# M471M_R1_S register map
File version: 1.0
Registers are 32-bit, read-write, reset 0x0 unless marked. A register's access mark holds for its fields unless they carry their own. Offsets are from the block's base; [hi:lo] are bit positions; {n}, {i} and the like mark numbered series; 'fields as' and 'values as' point back to an identical list.

## CLK — CLK Register Map
Base 0x40000200
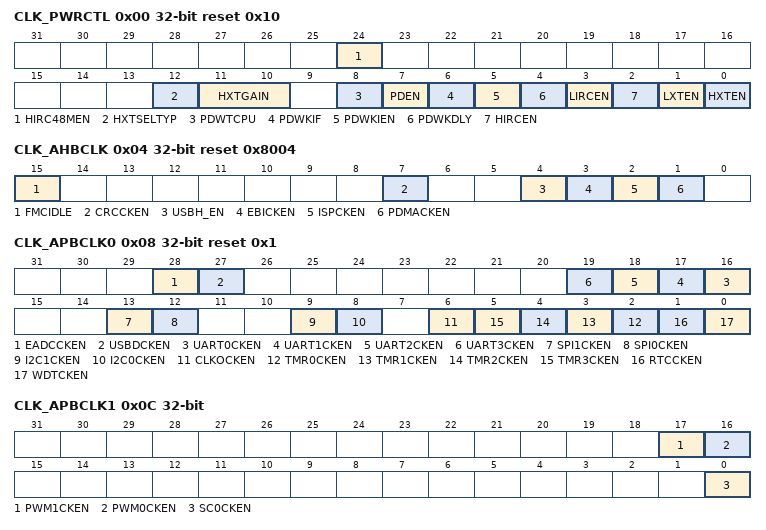
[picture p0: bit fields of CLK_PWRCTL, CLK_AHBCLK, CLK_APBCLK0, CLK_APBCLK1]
0x00 CLK_PWRCTL reset 0x10 (reset mask 0xFFFFFFF0) — System Power-down Control Register
  [24] HIRC48MEN — HIRC48M Enable Bit (Write Protect). Note: This bit is write protected. Refer to the SYS_REGLCTL register.
    0=48 MHz internal high speed RC oscillator (HIRC48M) Disabled; 1=48 MHz internal high speed RC oscillator (HIRC48M) Enabled
  [12] HXTSELTYP — HXT Crystal Type Select Bit (Write Protect). This is a protected register. Please refer to open lock sequence to program it. Note: This bit is write protected. Refer to the SYS_REGLCTL register.
    0=Select INV type; 1=Select GM type
  [11:10] HXTGAIN — HXT Gain Control Bit (Write Protect). This is a protected register. Please refer to open lock sequence to program it. Gain control is used to enlarge the gain of crystal to make sure crystal work normally. If gain control is enabled, crystal will consume more power than gain control off. Note: This bit is write protected. Refer to the SYS_REGLCTL register.
    0=HXT frequency is lower than from 8 MHz; 1=HXT frequency is from 8 MHz to 12 MHz; 2=HXT frequency is from 12 MHz to 16 MHz; 3=HXT frequency is higher than 16 MHz
  [8] PDWTCPU — this Bit Control the Power-down Entry Condition (Write Protect). Note: This bit is write protected. Refer to the SYS_REGLCTL register.
    0=Chip enters Power-down mode when the PDEN bit is set to 1; 1=Chip enters Power-down mode when the both PDWTCPU and PDEN bits are set to 1 and CPU runs WFI instruction
  [7] PDEN — System Power-down Enable (Write Protect). When this bit is set to 1, Power-down mode is enabled and chip Power-down behavior will depend on the PDWTCPU bit. (a) If the PDWTCPU is 0, then the chip enters Power-down mode immediately after the PDEN bit set. (default) (b) if the PDWTCPU is 1, then the chip keeps active till the CPU sleep mode is also active and then the chip enters Power-down mode. When chip wakes up from Power-down mode, this bit is auto cleared. Users need to set this bit again for next Power-down. In Power-down mode, HXT and the HIRC will be disabled in this mode, but LXT and LIRC are not controlled by Power-down mode. In Power-down mode, the PLL and system clock are disabled, and ignored the clock source selection. The clocks of peripheral are not controlled by Power-down mode, if the peripheral clock source is from LXT or LIRC. Note: This bit is write protected. Refer to the SYS_REGLCTL register.
    0=Chip operating normally or chip in idle mode because of WFI command; 1=Chip enters Power-down mode instant or wait CPU sleep command WFI
  [6] PDWKIF — Power-down Mode Wake-up Interrupt Status. Set by 'Power-down wake-up event', it indicates that resume from Power-down mode' The flag is set if the EINT0~5, GPIO, USBD, UART0~3, WDT, BOD, RTC, TMR0~3, I2C0~1 wake-up occurred. Note1: Write 1 to clear the bit to 0. Note2: This bit works only if PDWKIEN (CLK_PWRCTL[5]) set to 1.
  [5] PDWKIEN — Power-down Mode Wake-up Interrupt Enable Bit (Write Protect). Note1: The interrupt will occur when both PDWKIF and PDWKIEN are high. Note2: This bit is write protected. Refer to the SYS_REGLCTL register.
    0=Power-down mode wake-up interrupt Disabled; 1=Power-down mode wake-up interrupt Enabled
  [4] PDWKDLY — Enable the Wake-up Delay Counter (Write Protect). When the chip wakes up from Power-down mode, the clock control will delay certain clock cycles to wait system clock stable. The delayed clock cycle is 4096 clock cycles when chip works at 4~20 MHz external high speed crystal oscillator (HXT), and 256 clock cycles when chip works at 22.1184 MHz internal high speed RC oscillator (HIRC). Note: This bit is write protected. Refer to the SYS_REGLCTL register.
    0=Clock cycles delay Disabled; 1=Clock cycles delay Enabled
  [3] LIRCEN — LIRC Enable Bit (Write Protect). Note: This bit is write protected. Refer to the SYS_REGLCTL register.
    0=10 kHz internal low speed RC oscillator (LIRC) Disabled; 1=10 kHz internal low speed RC oscillator (LIRC) Enabled
  [2] HIRCEN — HIRC Enable Bit (Write Protect). Note: This bit is write protected. Refer to the SYS_REGLCTL register.
    0=22.1184 MHz internal high speed RC oscillator (HIRC) Disabled; 1=22.1184 MHz internal high speed RC oscillator (HIRC) Enabled
  [1] LXTEN — LXT Enable Bit (Write Protect). Note: This bit is write protected. Refer to the SYS_REGLCTL register.
    0=32.768 kHz external low speed crystal (LXT) Disabled; 1=32.768 kHz external low speed crystal (LXT) Enabled
  [0] HXTEN — HXT Enable Bit (Write Protect). The bit default value is set by flash controller user configuration register CONFIG0 [26:24]. When the default clock source is from HXT, this bit is set to 1 automatically. Note: This bit is write protected. Refer to the SYS_REGLCTL register.
    0=4~20 MHz xxternal high speed crystal (HXT) Disabled; 1=4~20 MHz external high speed crystal (HXT) Enabled
0x04 CLK_AHBCLK reset 0x8004 — AHB Devices Clock Enable Control Register
  [15] FMCIDLE — Flash Memory Controller Clock Enable Bit in IDLE Mode
    0=FMC peripheral clock Disabled when chip operating in IDLE mode; 1=FMC peripheral clock Enabled when chip operating in IDLE mode
  [7] CRCCKEN — CRC Generator Controller Clock Enable Bit
    0=CRC peripheral clock Disabled; 1=CRC peripheral clock Enabled
  [4] USBH_EN — USB HOST Controller Clock Enable Control
    0=USB HOST engine clock Disabled; 1=USB HOST engine clock Enabled
  [3] EBICKEN — EBI Controller Clock Enable Bit
    0=EBI peripheral clock Disabled; 1=EBI peripheral clock Enabled
  [2] ISPCKEN — Flash ISP Controller Clock Enable Bit
    0=Flash ISP peripheral clock Disabled; 1=Flash ISP peripheral clock Enabled
  [1] PDMACKEN — PDMA Controller Clock Enable Bit
    0=PDMA peripheral clock Disabled; 1=PDMA peripheral clock Enabled
0x08 CLK_APBCLK0 reset 0x1 — APB Devices Clock Enable Control Register 0
  [28] EADCCKEN — Enhanced Analog-digital-converter (EADC) Clock Enable Bit
    0=EADC clock Disabled; 1=EADC clock Enabled
  [27] USBDCKEN — USB Device Clock Enable Bit
    0=USB Device clock Disabled; 1=USB Device clock Enabled
  [n+16] UART{n}CKEN (n=0..3) — UART{n} Clock Enable Bit
    0=UART{n} clock Disabled; 1=UART{n} clock Enabled
  [13] SPI1CKEN — SPI1 Clock Enable Bit
    0=SPI1 clock Disabled; 1=SPI1 clock Enabled
  [12] SPI0CKEN — SPI0 Clock Enable Bit
    0=SPI0 clock Disabled; 1=SPI0 clock Enabled
  [9] I2C1CKEN — I2C1 Clock Enable Bit
    0=I2C1 clock Disabled; 1=I2C1 clock Enabled
  [8] I2C0CKEN — I2C0 Clock Enable Bit
    0=I2C0 clock Disabled; 1=I2C0 clock Enabled
  [6] CLKOCKEN — CLKO Clock Enable Bit
    0=CLKO clock Disabled; 1=CLKO clock Enabled
  [n+2] TMR{n}CKEN (n=0..3) — Timer{n} Clock Enable Bit
    0=Timer{n} clock Disabled; 1=Timer{n} clock Enabled
  [1] RTCCKEN — Real-time-clock APB Interface Clock Enable Bit. This bit is used to control the RTC APB clock only. The RTC peripheral clock source is selected from RTCSEL(CLK_CLKSEL3[8]). It can be selected to 32.768 kHz external low speed crystal or 10 kHz internal low speed RC oscillator (LIRC).
    0=RTC APB clock Disabled; 1=RTC APB clock Enabled
  [0] WDTCKEN — Watchdog Timer Clock Enable Bit (Write Protect). Note: This bit is write protected. Refer to the SYS_REGLCTL register.
    0=Watchdog timer clock Disabled; 1=Watchdog timer clock Enabled
0x0C CLK_APBCLK1 — APB Devices Clock Enable Control Register 1
  [17] PWM1CKEN — PWM1 Clock Enable Bit
    0=PWM1 clock Disabled; 1=PWM1 clock Enabled
  [16] PWM0CKEN — PWM0 Clock Enable Bit
    0=PWM0 clock Disabled; 1=PWM0 clock Enabled
  [0] SC0CKEN — SC0 Clock Enable Bit
    0=SC0 clock Disabled; 1=SC0 clock Enabled
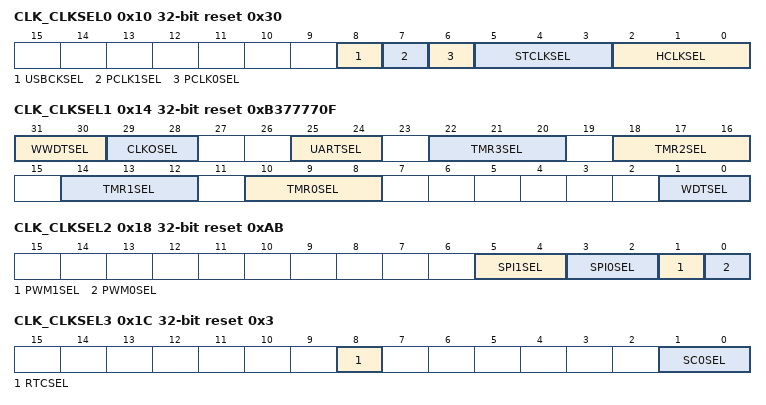
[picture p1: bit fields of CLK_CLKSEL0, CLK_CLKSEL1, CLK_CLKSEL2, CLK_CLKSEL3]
0x10 CLK_CLKSEL0 reset 0x30 (reset mask 0xFFFFFFF0) — Clock Source Select Control Register 0
  [8] USBCKSEL — USB Clock Source Selection (Write Protect). Note: This bit is write protected. Refer to the SYS_REGLCTL register.
    0=USBH and USBD clock source from PLL; 1=USBH and USBD clock source from HIRC48M
  [7] PCLK1SEL — PCLK1 Clock Source Selection (Write Protect). Note: This bit is write protected. Refer to the SYS_REGLCTL register.
    0=APB1 bUS clock source from HCLK; 1=APB1 bUS clock source from HCLK/2
  [6] PCLK0SEL — PCLK0 Clock Source Selection (Write Protect). Note: This bit is write protected. Refer to the SYS_REGLCTL register.
    0=APB0 bUS clock source from HCLK; 1=APB0 bUS clock source from HCLK/2
  [5:3] STCLKSEL — Cortex-M4 SysTick Clock Source Selection (Write Protect). Note: This bit is write protected. Refer to the SYS_REGLCTL register.
    0=Clock source from HXT; 1=Clock source from LXT; 2=Clock source from HXT/2; 3=Clock source from HCLK/2; 7=Clock source from HIRC/2
  [2:0] HCLKSEL — HCLK Clock Source Selection (Write Protect). Before clock switching, the related clock sources (both pre-select and new-select) must be turned on. The default value is reloaded from the value of CFOSC (CONFIG0[26:24]) in user configuration register of Flash controller by any reset. Therefore the default value is either 000b or 111b. Note: This bit is write protected. Refer to the SYS_REGLCTL register.
    0=Clock source from HXT; 1=Clock source from LXT; 2=Clock source from PLL; 3=Clock source from LIRC; 7=Clock source from HIRC
0x14 CLK_CLKSEL1 reset 0xB377770F — Clock Source Select Control Register 1
  [31:30] WWDTSEL — Window Watchdog Timer Clock Source Selection
    2=Clock source from HCLK/2048; 3=Clock source from 10 kHz internal low speed RC oscillator (LIRC)
  [29:28] CLKOSEL — Clock Divider Clock Source Selection
    0=Clock source from 4~20 MHz external high speed crystal oscillator (HXT); 1=Clock source from 32.768 kHz external low speed crystal oscillator (LXT); 2=Clock source from HCLK; 3=Clock source from 22.1184 MHz internal high speed RC oscillator (HIRC)
  [25:24] UARTSEL — UART Clock Source Selection
    0=Clock source from 4~20 MHz external high speed crystal oscillator (HXT); 1=Clock source from PLL; 2=Clock source from 32.768 kHz external low speed crystal oscillator (LXT); 3=Clock source from 22.1184 MHz internal high speed RC oscillator (HIRC)
  [22:20] TMR3SEL — TIMER3 Clock Source Selection
    0=Clock source from 4~20 MHz external high speed crystal oscillator (HXT); 1=Clock source from 32.768 kHz external low speed crystal oscillator (LXT); 2=Clock source from PCLK1; 3=Clock source from external clock T3 pin; 5=Clock source from 10 kHz internal low speed RC oscillator (LIRC); 7=Clock source from 22.1184 MHz internal high speed RC oscillator (HIRC)
  [18:16] TMR2SEL — TIMER2 Clock Source Selection
    0=Clock source from 4~20 MHz external high speed crystal oscillator (HXT); 1=Clock source from 32.768 kHz external low speed crystal oscillator (LXT); 2=Clock source from PCLK1; 3=Clock source from external clock T2 pin; 5=Clock source from 10 kHz internal low speed RC oscillator (LIRC); 7=Clock source from 22.1184 MHz internal high speed RC oscillator (HIRC)
  [14:12] TMR1SEL — TIMER1 Clock Source Selection
    0=Clock source from 4~20 MHz external high speed crystal oscillator (HXT); 1=Clock source from 32.768 kHz external low speed crystal oscillator (LXT); 2=Clock source from PCLK0; 3=Clock source from external clock T1 pin; 5=Clock source from 10 kHz internal low speed RC oscillator (LIRC); 7=Clock source from 22.1184 MHz internal high speed RC oscillator (HIRC)
  [10:8] TMR0SEL — TIMER0 Clock Source Selection
    0=Clock source from 4~20 MHz external high speed crystal oscillator (HXT); 1=Clock source from 32.768 kHz external low speed crystal oscillator (LXT); 2=Clock source from PCLK0; 3=Clock source from external clock T0 pin; 5=Clock source from 10 kHz internal low speed RC oscillator (LIRC); 7=Clock source from 22.1184 MHz internal high speed RC oscillator (HIRC)
  [1:0] WDTSEL — Watchdog Timer Clock Source Selection (Write Protect). Note: This bit is write protected. Refer to the SYS_REGLCTL register.
    1=Clock source from 32.768 kHz external low speed crystal oscillator (LXT); 2=Clock source from HCLK/2048; 3=Clock source from 10 kHz internal low speed RC oscillator (LIRC)
0x18 CLK_CLKSEL2 reset 0xAB — Clock Source Select Control Register 2
  [5:4] SPI1SEL — SPI1 Clock Source Selection
    0=Clock source from 4~20 MHz external high speed crystal oscillator (HXT); 1=Clock source from PLL; 2=Clock source from PCLK1; 3=Clock source from 22.1184 MHz internal high speed RC oscillator (HIRC)
  [3:2] SPI0SEL — SPI0 Clock Source Selection
    0=Clock source from 4~20 MHz external high speed crystal oscillator (HXT); 1=Clock source from PLL; 2=Clock source from PCLK0; 3=Clock source from 22.1184 MHz internal high speed RC oscillator (HIRC)
  [1] PWM1SEL — PWM1 Clock Source Selection. The peripheral clock source of PWM1 is defined by PWM1SEL.
    0=Clock source from PLL; 1=Clock source from PCLK1
  [0] PWM0SEL — PWM0 Clock Source Selection. The peripheral clock source of PWM0 is defined by PWM0SEL.
    0=Clock source from PLL; 1=Clock source from PCLK0
0x1C CLK_CLKSEL3 reset 0x3 — Clock Source Select Control Register 3
  [8] RTCSEL — RTC Clock Source Selection
    0=Clock source from 32.768 kHz external low speed crystal oscillator (LXT); 1=Clock source from 10 kHz internal low speed RC oscillator (LIRC)
  [1:0] SC0SEL — SC0 Clock Source Selection
    values as CLK_CLKSEL2.SPI0SEL
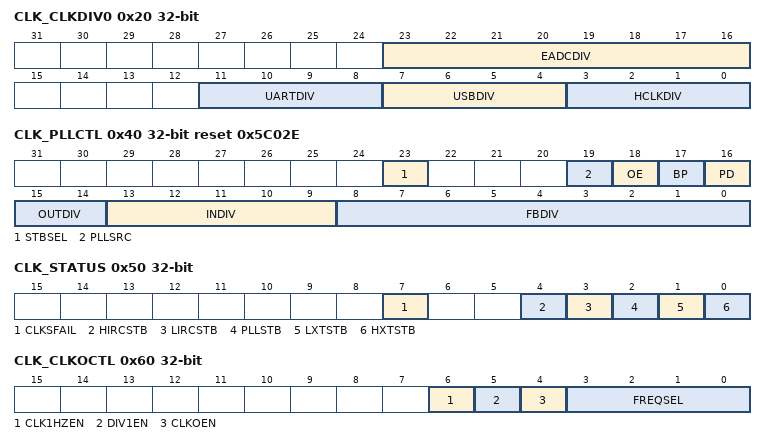
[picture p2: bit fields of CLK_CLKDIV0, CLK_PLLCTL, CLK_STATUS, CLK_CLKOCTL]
0x20 CLK_CLKDIV0 — Clock Divider Number Register 0
  [23:16] EADCDIV — EADC Clock Divide Number From EADC Clock Source
  [11:8] UARTDIV — UART Clock Divide Number From UART Clock Source
  [7:4] USBDIV — USB Clock Divide Number From PLL Clock
  [3:0] HCLKDIV — HCLK Clock Divide Number From HCLK Clock Source
0x24 CLK_CLKDIV1 — Clock Divider Number Register 1
  [7:0] SC0DIV — SC0 Clock Divide Number From SC0 Clock Source
0x40 CLK_PLLCTL reset 0x5C02E — PLL Control Register
  [23] STBSEL — PLL Stable Counter Selection (Write Protect). Note: This bit is write protected. Refer to the SYS_REGLCTL register.
    0=PLL stable time is 6144 PLL source clock (suitable for source clock is equal to or less than 12 MHz); 1=PLL stable time is 12288 PLL source clock (suitable for source clock is larger than 12 MHz)
  [19] PLLSRC — PLL Source Clock Selection (Write Protect). Note: This bit is write protected. Refer to the SYS_REGLCTL register.
    0=PLL source clock from 4~20 MHz external high-speed crystal oscillator (HXT); 1=PLL source clock from 22.1184 MHz internal high-speed oscillator (HIRC)
  [18] OE — PLL OE (FOUT Enable) Pin Control (Write Protect). Note: This bit is write protected. Refer to the SYS_REGLCTL register.
    0=PLL FOUT Enabled; 1=PLL FOUT is fixed low
  [17] BP — PLL Bypass Control (Write Protect). Note: This bit is write protected. Refer to the SYS_REGLCTL register.
    0=PLL is in normal mode (default); 1=PLL clock output is same as PLL input clock FIN
  [16] PD — Power-down Mode (Write Protect). If set the PDEN bit to 1 in CLK_PWRCTL register, the PLL will enter Power-down mode, too. Note: This bit is write protected. Refer to the SYS_REGLCTL register.
    0=PLL is in normal mode; 1=PLL is in Power-down mode (default)
  [15:14] OUTDIV — PLL Output Divider Control (Write Protect). Refer to the formulas below the table. Note: This bit is write protected. Refer to the SYS_REGLCTL register.
  [13:9] INDIV — PLL Input Divider Control (Write Protect). Refer to the formulas below the table. Note: This bit is write protected. Refer to the SYS_REGLCTL register.
  [8:0] FBDIV — PLL Feedback Divider Control (Write Protect). Refer to the formulas below the table. Note: This bit is write protected. Refer to the SYS_REGLCTL register.
0x50 CLK_STATUS ro (reset mask 0xFFFFFF00) — Clock Status Monitor Register
  [7] CLKSFAIL — Clock Switching Fail Flag (Read Only). This bit is updated when software switches system clock source. If switch target clock is stable, this bit will be set to 0. If switch target clock is not stable, this bit will be set to 1. Note: Write 1 to clear the bit to 0.
    0=Clock switching success; 1=Clock switching failure
  [4] HIRCSTB — HIRC Clock Source Stable Flag (Read Only)
    0=22.1184 MHz internal high speed RC oscillator (HIRC) clock is not stable or disabled; 1=22.1184 MHz internal high speed RC oscillator (HIRC) clock is stabe and enabled
  [3] LIRCSTB — LIRC Clock Source Stable Flag (Read Only)
    0=10 kHz internal low speed RC oscillator (LIRC) clock is not stable or disabled; 1=10 kHz internal low speed RC oscillator (LIRC) clock is stable and enabled
  [2] PLLSTB — Internal PLL Clock Source Stable Flag (Read Only)
    0=Internal PLL clock is not stable or disabled; 1=Internal PLL clock is stable and enabled
  [1] LXTSTB — LXT Clock Source Stable Flag (Read Only)
    0=32.768 kHz external low speed crystal oscillator (LXT) clock is not stable or disabled; 1=32.768 kHz external low speed crystal oscillator (LXT) clock is stabled and enabled
  [0] HXTSTB — HXT Clock Source Stable Flag (Read Only)
    0=4~20 MHz external high speed crystal oscillator (HXT) clock is not stable or disabled; 1=4~20 MHz external high speed crystal oscillator (HXT) clock is stable and enabled
0x60 CLK_CLKOCTL — Clock Output Control Register
  [6] CLK1HZEN — Clock Output 1Hz Enable Bit
    0=1 Hz clock output for 32.768 kHz frequency compensation Disabled; 1=1 Hz clock output for 32.768 kHz frequency compensation Enabled
  [5] DIV1EN — Clock Output Divide One Enable Bit
    0=Clock Output will output clock with source frequency divided by FREQSEL; 1=Clock Output will output clock with source frequency
  [4] CLKOEN — Clock Output Enable Bit
    0=Clock Output function Disabled; 1=Clock Output function Enabled
  [3:0] FREQSEL — Clock Output Frequency Selection. The formula of output frequency is. Fin is the input clock frequency. Fout is the frequency of divider output clock. N is the 4-bit value of FREQSEL[3:0].
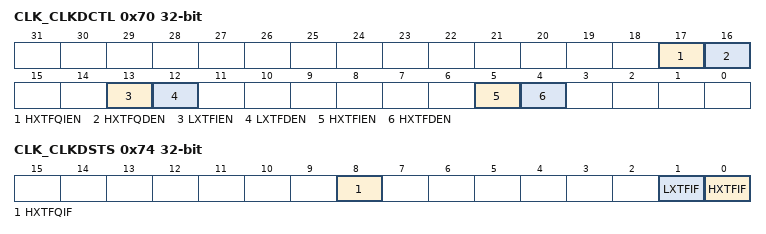
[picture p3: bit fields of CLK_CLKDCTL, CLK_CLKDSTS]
0x70 CLK_CLKDCTL — Clock Fail Detector Control Register
  [17] HXTFQIEN — HXT Clock Frequency Monitor Interrupt Enable Bit
    0=4~20 MHz external high speed crystal oscillator (HXT) clock frequency monitor fail interrupt Disabled; 1=4~20 MHz external high speed crystal oscillator (HXT) clock frequency monitor fail interrupt Enabled
  [16] HXTFQDEN — HXT Clock Frequency Monitor Enable Bit
    0=4~20 MHz external high speed crystal oscillator (HXT) clock frequency monitor Disabled; 1=4~20 MHz external high speed crystal oscillator (HXT) clock frequency monitor Enabled
  [13] LXTFIEN — LXT Clock Fail Interrupt Enable Bit
    0=32.768 kHz external low speed crystal oscillator (LXT) clock fail interrupt Disabled; 1=32.768 kHz external low speed crystal oscillator (LXT) clock fail interrupt Enabled
  [12] LXTFDEN — LXT Clock Fail Detector Enable Bit
    0=32.768 kHz external low speed crystal oscillator (LXT) clock fail detector Disabled; 1=32.768 kHz external low speed crystal oscillator (LXT) clock fail detector Enabled
  [5] HXTFIEN — HXT Clock Fail Interrupt Enable Bit
    0=4~20 MHz external high speed crystal oscillator (HXT) clock fail interrupt Disabled; 1=4~20 MHz external high speed crystal oscillator (HXT) clock fail interrupt Enabled
  [4] HXTFDEN — HXT Clock Fail Detector Enable Bit
    0=4~20 MHz external high speed crystal oscillator (HXT) clock fail detector Disabled; 1=4~20 MHz external high speed crystal oscillator (HXT) clock fail detector Enabled
0x74 CLK_CLKDSTS — Clock Fail Detector Status Register
  [8] HXTFQIF — HXT Clock Frequency Monitor Interrupt Flag. Note: Write 1 to clear the bit to 0.
    0=4~20 MHz external high speed crystal oscillator (HXT) clock is normal; 1=4~20 MHz external high speed crystal oscillator (HXT) clock frequency is abnormal
  [1] LXTFIF — LXT Clock Fail Interrupt Flag. Note: Write 1 to clear the bit to 0.
    0=32.768 kHz external low speed crystal oscillator (LXT) clock is normal; 1=32.768 kHz external low speed crystal oscillator (LXT) stops
  [0] HXTFIF — HXT Clock Fail Interrupt Flag. Note: Write 1 to clear the bit to 0.
    0=4~20 MHz external high speed crystal oscillator (HXT) clock is normal; 1=4~20 MHz external high speed crystal oscillator (HXT) clock stops
0x78 CLK_CDUPB — Clock Frequency Detector Upper Boundary Register
  [9:0] UPERBD — HXT Clock Frequency Detector Upper Boundary. The bits define the high value of frequency monitor window. When HXT frequency monitor value higher than this register, the HXT frequency detect fail interrupt flag will set to 1.
0x7C CLK_CDLOWB — Clock Frequency Detector Lower Boundary Register
  [9:0] LOWERBD — HXT Clock Frequency Detector Lower Boundary. The bits define the low value of frequency monitor window. When HXT frequency monitor value lower than this register, the HXT frequency detect fail interrupt flag will set to 1.
